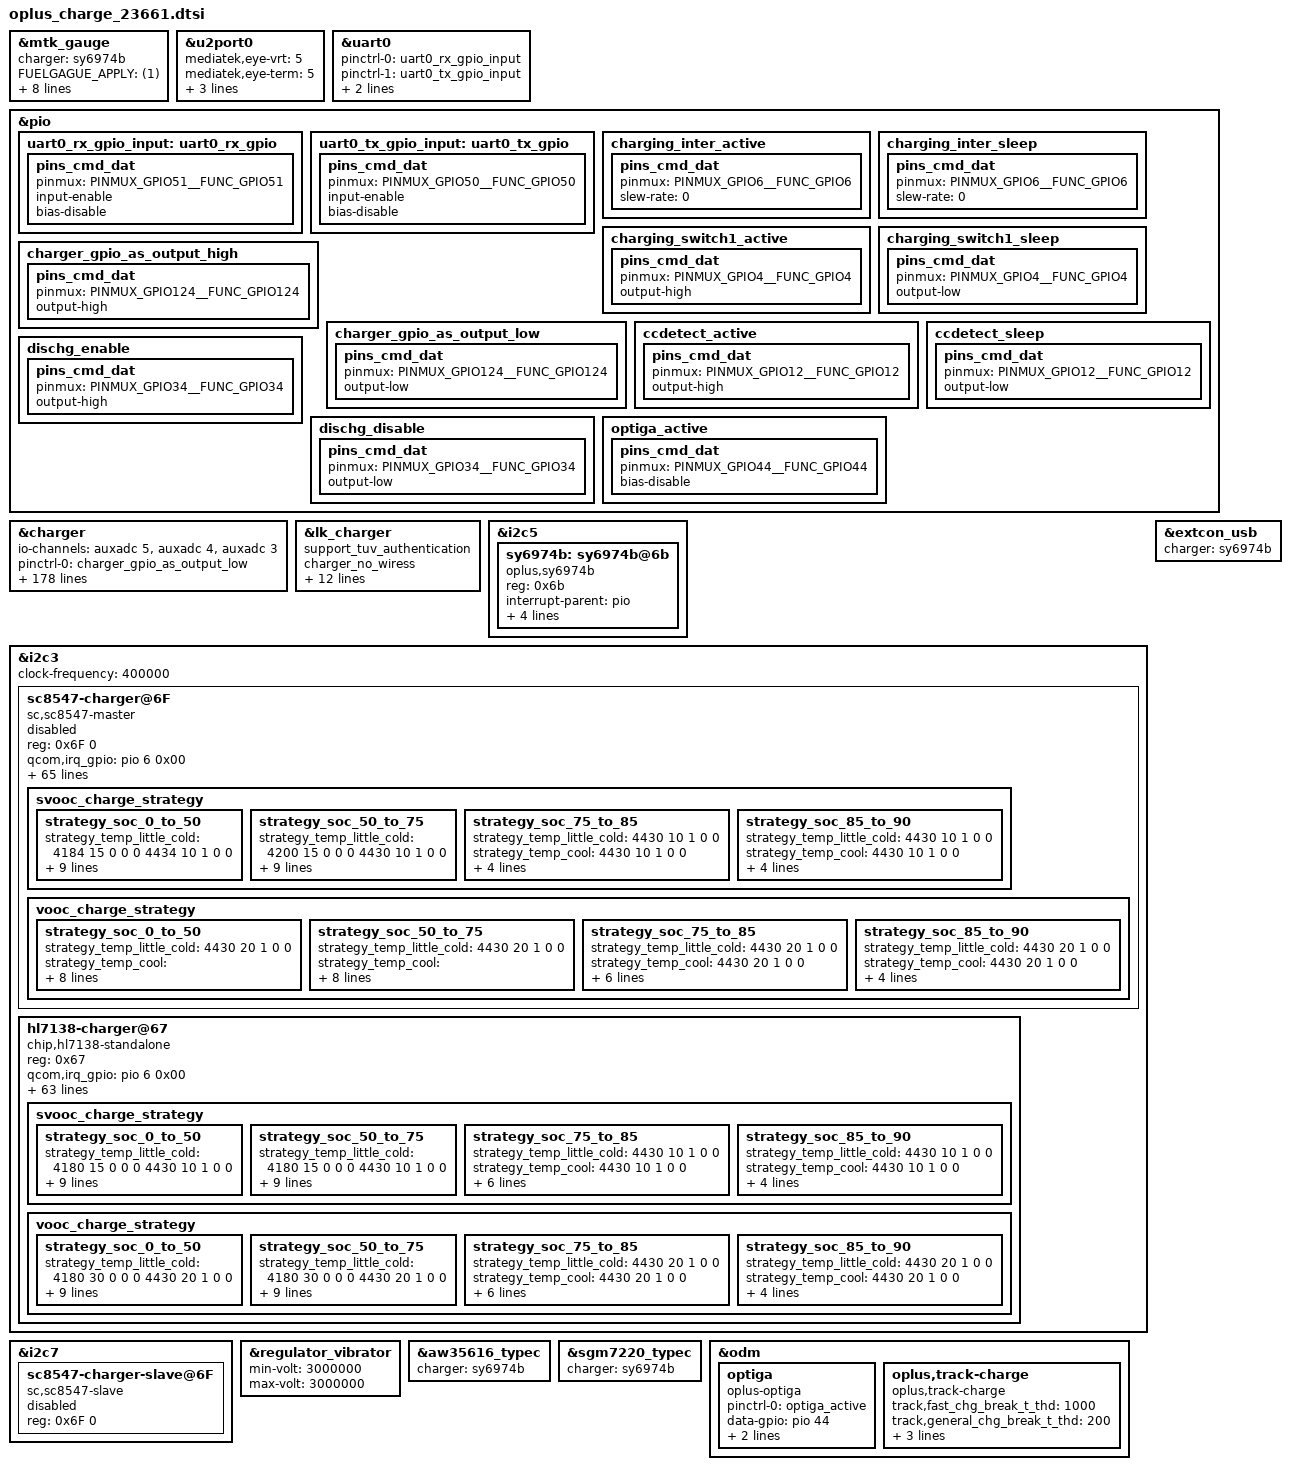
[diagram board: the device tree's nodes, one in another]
// SPDX-License-Identifier: GPL-2.0-only
/*
* Copyright (C) 2021-2020 Oplus. All rights reserved.
*/

/*
 *
 * CPU:MT6835 Chongqing
 * UTXD0 -->GPIO50
 * URXD0 -->GPIO51
 * I2C
 * MASTER_CHG/CCLOGIC --> I2C5
 * IRQB
 * EINT_CHG_1 (cp1 irq)                -->GPIO6
 * EINT_CHG_2 (cp2 irq)                -->GPIO18
 * CC_CNTL_INT_N(cc login irq)          --> GPIO12
 * CHG_INT(main irq)           --> GPIO3
 *
 * GPIO
 * MAIN/CCLOGIN_SCL               --> GPIO137(SCL5)
 * MAIN/CCLOGIN_SDA               --> GPIO138(SDA5)
 * USB_SWITCH_2(uart/vooc switch)      --> GPIO4
 * VBUS_SHORT(防烧口)           --> GPIO34
 * CHARGER_PUMP1_SCL               --> GPIO133(CP1_SCL3)
 * CHARGER_PUMP1_SDA               --> GPIO134(CP1_SDA3)
 * CHARGER_PUMP2_SCL               --> GPIO141(CP2_SCL7)
 * CHARGER_PUMP2_SDA               --> GPIO142(CP2_SDA7)
 * USB_SWITCH_1(usb/uart&vooc switch)    --> GPIO124
 * SEC_IC (加密电池GPIO for 67W)    --> GPIO44
 *
 * AP_AUXADC:
 * 0				--> FLASH_LED1_NTC
 * 1				--> NTC_USBCON_TEM (BTB VBUS旁)
 * 2				--> NTC_CHARGE (充电IC旁)
 * 3				--> USB_TEM2_ADC (BB_USB_ADC2 r/l?)
 * 4				--> USB_TEM1_ADC (BB_USB_ADC1)
 * 5				--> BAT_ID_ADC_OUT   (注意：33W 时用的是BAT_ID_ADC_OUT ,67W时用的是 BATThermal_1)
 * 6				--> NTC_charging （充电座子旁）
 * 7				-->
 * 8				-->
 */


#include <dt-bindings/iio/mt635x-auxadc.h>
#include <dt-bindings/pinctrl/mt6373-pinfunc.h>
#include <dt-bindings/pinctrl/mt65xx.h>
#include "oplus_chg.h"
/* charge start */

&mtk_gauge {
	status = "okay";
	charger = <&sy6974b>;
	FUELGAGUE_APPLY = <(1)>;
	BATT_ID_FAST_CHECK = <(1)>;
	io-channels = <&pmic_adc AUXADC_BAT_TEMP>,
				<&pmic_adc AUXADC_BATADC>,
				<&pmic_adc AUXADC_VBIF>,
				<&pmic_adc AUXADC_IMP>,
				<&pmic_adc AUXADC_IMIX_R>,
				<&pmic_adc AUXADC_VCDT>,
				<&auxadc 5>;
	io-channel-names = "pmic_battery_temp",
					"pmic_battery_voltage",
					"pmic_bif_voltage",
					"pmic_ptim_voltage",
					"pmic_ptim_r",
					"pmic_vcdt_voltage",
					 "auxadc5-batt_id_v";


    //IS_SUBBOARD_TEMP_SUPPORT = <(1)>;
	Enable_Is_Force_Full = <(1)>;
	DIM2_TABLE_DISTINGUISH = <(1)>;
	#include "mediatek/bat_setting/mt6835_chongqing_battery_table_33w.dtsi"
	#include "mediatek/bat_setting/mt6835_chongqing_battery_prop_dim2_ext_33w.dtsi"
};

&u2port0 {
    mediatek,eye-vrt = <5>;
    mediatek,eye-term = <5>;
    mediatek,rev4 = <1>;
    mediatek,discth = <9>;
    mediatek,rx-sqth = <5>;
};


&uart0 {
	pinctrl-names = "uart0_rx_gpio", "uart0_tx_gpio";
	pinctrl-0 = <&uart0_rx_gpio_input>;
	pinctrl-1 = <&uart0_tx_gpio_input>;
	status = "okay";

	txpin = <50>;
	rxpin = <51>;
};

&pio {
	uart0_rx_gpio_input: uart0_rx_gpio {
		pins_cmd_dat {
			pinmux = <PINMUX_GPIO51__FUNC_GPIO51>;
			input-enable;
			bias-disable;
		};
	};

	uart0_tx_gpio_input: uart0_tx_gpio {
		pins_cmd_dat {
			pinmux = <PINMUX_GPIO50__FUNC_GPIO50>;
			input-enable;
			bias-disable;
		};
	};
};


&charger {
//auxadc5temp 待配置，doki上是sub_bat_tem
	io-channels = <&auxadc 5>,<&auxadc 4>,<&auxadc 3>;
	io-channel-names = "auxadc5temp","usb_temp_v_l","usb_temp_v_r";

	pinctrl-names = "charger_gpio_as_output_low","charger_gpio_as_output_high",
					"ccdetect_active","ccdetect_sleep","dischg_enable","dischg_disable";
	pinctrl-0 = <&charger_gpio_as_output_low>;
	pinctrl-1 = <&charger_gpio_as_output_high>;
	pinctrl-2 = <&ccdetect_active>;
	pinctrl-3 = <&ccdetect_sleep>;
	pinctrl-4 = <&dischg_enable>;
	pinctrl-5 = <&dischg_disable>;

	gauge = <&mtk_gauge>;
	charger = <&sy6974b>;

	//for oplus chg framework:
	qcom,pps_support_type = <0>;
	qcom,pd_input_current_charger_ma = <2000>;
	qcom,qc_input_current_charger_ma = <2000>;
	qcom,input_current_charger_ma = <2200>;
	qcom,input_current_usb_ma = <500>;
	qcom,input_current_cdp_ma = <1500>;
	qcom,input_current_camera_ma = <1200>;
	qcom,input_current_calling_ma = <1500>;

	qcom,led_warm_bat_decidegc = <350>;
	qcom,led_high_bat_decidegc = <370>;
	qcom,input_current_led_ma = <1200>;
	qcom,input_current_led_ma_high = <1200>;
	qcom,input_current_led_ma_warm = <1500>;
	qcom,input_current_led_ma_normal = <2000>;
	qcom,input_current_led_ma_forcmcc = <500>;
	qcom,input_current_led_ma_limit_high = <1200>;

	qcom,vooc_temp_bat_normal_decidegc = <350>;
	qcom,vooc_temp_bat_warm_decidegc = <370>;
	qcom,vooc_temp_bat_hot_decidegc = <440>;
	qcom,input_current_vooc_led_ma_high = <1200>;
	qcom,input_current_vooc_led_ma_warm = <1800>;
	qcom,input_current_vooc_led_ma_normal = <3600>;
	qcom,input_current_vooc_ma_normal = <3600>;
	qcom,input_current_vooc_ma_warm = <3200>;
	qcom,input_current_vooc_ma_high = <2200>;

	qcom,overtemp_bat_decidegc = <400>;
	qcom,iterm_disabled = <0>;
	//sw_full_count = <25>;
	qcom,iterm_ma = <255>;
	qcom,recharge-mv = <100>;

	qcom,batt_capacity_mah = <5000>; /*typical capacity*/
	qcom,usb_high_than_bat_decidegc = <168>;

	qcom,removed_bat_decidegc = <400>;  /* < -15C */

	qcom,cold_bat_decidegc = <100>;  /* -10C ~ 0C */
	qcom,temp_cold_vfloat_mv = <4435>;
	qcom,temp_freeze_fastchg_current_ma_high = <900>;
	qcom,temp_freeze_fastchg_current_ma_low = <900>;
	qcom,temp_freeze_fastchg_current_ma = <900>;
	qcom,temp_cold_fastchg_current_ma = <900>;

	qcom,little_cold_bat_decidegc = <0>;    /* 0C ~ 5C */
	qcom,temp_little_cold_vfloat_mv = <4435>;
	qcom,temp_little_cold_fastchg_current_ma_high = <2200>;
	qcom,temp_little_cold_fastchg_current_ma_low = <2200>;
	qcom,temp_little_cold_fastchg_current_ma = <2200>;
	qcom,qc_temp_little_cold_fastchg_current_ma_high = <2594>;
	qcom,qc_temp_little_cold_fastchg_current_ma_low = <3300>;
	qcom,pd_temp_little_cold_fastchg_current_ma_high = <2594>;
	qcom,pd_temp_little_cold_fastchg_current_ma_low = <3300>;

	qcom,cool_bat_decidegc = <50>;  /* 5C ~ 12C */
	qcom,temp_cool_vfloat_mv = <4435>;
	qcom,temp_cool_fastchg_current_ma_high = <2200>;
	qcom,temp_cool_fastchg_current_ma_low = <2200>;
	qcom,qc_temp_cool_fastchg_current_ma_high = <3300>;
	qcom,qc_temp_cool_fastchg_current_ma_low = <3300>;
	qcom,pd_temp_cool_fastchg_current_ma_high = <3300>;
	qcom,pd_temp_cool_fastchg_current_ma_low = <3300>;

	qcom,little_cool_bat_decidegc = <120>;  /* 12C ~ 16C */
	qcom,temp_little_cool_vfloat_mv = <4435>;
	qcom,temp_little_cool_fastchg_current_ma = <2200>;
	qcom,pd_temp_little_cool_fastchg_current_ma = <3300>;
	qcom,qc_temp_little_cool_fastchg_current_ma = <3300>;

	qcom,normal_bat_decidegc = <160>;       /* 16C ~ 45C */
	qcom,temp_normal_vfloat_mv = <4435>;
	qcom,temp_normal_fastchg_current_ma = <2200>;
	qcom,pd_temp_normal_fastchg_current_ma = <3300>;
	qcom,qc_temp_normal_fastchg_current_ma = <3300>;

	qcom,warm_bat_decidegc = <450>;         /* 45C ~ 53C */ /*8pin Bat Vooc project need add 3 degree C*/
	qcom,temp_warm_vfloat_mv = <4130>;
	qcom,temp_warm_fastchg_current_ma = <1300>;
	qcom,pd_temp_warm_fastchg_current_ma = <1300>;
	qcom,qc_temp_warm_fastchg_current_ma = <1300>;
	qcom,temp_warm_fastchg_current_ma_led_on = <500>;

	qcom,hot_bat_decidegc = <530>;  /* > 53C */

	qcom,non_standard_vfloat_mv = <3980>;
	qcom,non_standard_fastchg_current_ma = <512>;

	qcom,short_c_bat_cv_mv = <4330>;
	qcom,short_c_bat_vfloat_mv = <3800>;
	qcom,short_c_bat_fastchg_current_ma = <512>;
	qcom,short_c_bat_vfloat_sw_limit = <3750>;

	qcom,cold_vfloat_sw_limit = <4385>;
	qcom,little_cold_vfloat_sw_limit = <4385>;
	qcom,cool_vfloat_sw_limit = <4385>;
	qcom,little_cool_vfloat_sw_limit = <4385>;
	qcom,normal_vfloat_sw_limit = <4385>;
	qcom,warm_vfloat_sw_limit = <4080>;
	qcom,non_standard_vfloat_sw_limit = <3930>;

	qcom,max_chg_time_sec = <72000>;
	qcom,charger_hv_thr = <10000>;
	qcom,charger_recv_thr = <9800>;
	qcom,charger_lv_thr = <3400>;
	qcom,vbatt_full_thr = <4400>;
	qcom,vbatt_hv_thr = <4600>;

	qcom,vfloat_step_mv = <16>;
	qcom,non_standard_vfloat_over_sw_limit = <3990>;
	qcom,cold_vfloat_over_sw_limit = <4445>;
	qcom,little_cold_vfloat_over_sw_limit = <4445>;
	qcom,cool_vfloat_over_sw_limit = <4445>;
	qcom,little_cool_vfloat_over_sw_limit = <4445>;
	qcom,normal_vfloat_over_sw_limit = <4440>;
	qcom,warm_vfloat_over_sw_limit = <4140>;

	qcom,vbatt_power_off = <3300>;
	qcom,vbatt_soc_1 = <3410>;
	qcom,vooc_project = <5>;
	qcom,vbatt_num = <1>;
	qcom,new_ui_warning_support;
	qcom,smart_charging_screenoff;
	qcom,smart_charge_version = <1>;

	qcom,normal_vterm_hw_inc = <18>;
	qcom,non_normal_vterm_hw_inc = <18>;
	qcom,usbtemp_batttemp_gap = <12>;

	qcom,ff1_normal_fastchg_ma = <1500>; /*12C~35c*/
	qcom,ff1_warm_fastchg_ma = <1500>;	/* 35C ~ 40c */
	qcom,ff1_exit_step_ma = <400>;
	qcom,ff1_warm_exit_step_ma = <300>;

	qcom,ffc2_normal_fastchg_ma = <1200>;/*12C~35c*/
	qcom,ffc2_warm_fastchg_ma = <1300>;	/* 35C ~ 40c */
	qcom,ffc2_temp_warm_decidegc = <350>;
	qcom,ffc2_temp_high_decidegc = <400>;
	qcom,ffc2_temp_low_decidegc = <120>;
	qcom,ffc2_exit_step_ma = <100>;
	qcom,ffc2_warm_exit_step_ma = <100>;

	qcom,ffc_normal_vfloat_sw_limit = <4475>;
	qcom,ffc_temp_normal_vfloat_mv = <4550>;
	qcom,ffc_normal_vfloat_over_sw_limit = <4550>;
	qcom,ffc_warm_vfloat_sw_limit = <4475>;

	qcom,ffc2_normal_vfloat_sw_limit = <4475>;
	qcom,ffc2_temp_normal_vfloat_mv = <4550>;
	qcom,ffc2_normal_vfloat_over_sw_limit = <4550>;
	qcom,ffc2_warm_vfloat_sw_limit = <4475>;


	qcom,default_iterm_ma = <255>;
	qcom,default_temp_normal_fastchg_current_ma = <2200>;
	qcom,default_normal_vfloat_sw_limit = <4385>;
	qcom,default_temp_normal_vfloat_mv = <4435>;
	qcom,default_normal_vfloat_over_sw_limit = <4445>;

	qcom,default_temp_little_cool_fastchg_current_ma = <2200>;
	qcom,default_little_cool_vfloat_sw_limit = <4385>;
	qcom,default_temp_little_cool_vfloat_mv = <4435>;
	qcom,default_little_cool_vfloat_over_sw_limit = <4445>;

	//for PD9V or QC9V
	qcom,vbatt_pdqc_to_5v_thr = <4500>;
	qcom,vbatt_pdqc_to_9v_thr = <4500>;

	//for control:
	//qcom,suspend_after_full;
	qcom,check_batt_full_by_sw;
	qcom,chg_ctrl_by_lcd;
	qcom,chg_ctrl_by_camera;
	qcom,chg_ctrl_by_calling;
	qcom,sw_vfloat_over_protect_enable;
	qcom,usbtemp_dischg_by_platpmic;
	qcom,ffc_support;
	qcom,chargerid_vol_disable;
	qcom,support_ntc_01c_precision;
	qcom,voocphy_support = <2>;
	//qcom,external_authenticate;
	qcom,chargerid_support;
	qcom,vooc_show_ui_soc_decimal;
	qcom,ui_soc_decimal_speedmin = <20>;//2A
	qcom,ccdetect_by_wd0;
	qcom,hvdcp_disabled; //do'not supprot hvdcp
	//GPIO config:
	qcom,chargerid_switch-gpio = <&pio 124 0x00>;/*USB_SWITCH_1*/
	qcom,dischg-gpio = <&pio 34 0x00>;/*VBUS_SHORT*/
	//qcom,ccdetect-gpio = <&pio 3 0x00>;

	qcom,vooc-max-input-volt-support = <10000>;     //10V
	qcom,vooc-max-input-current-support = <3000>;   //3A
};

&lk_charger {
	support_tuv_authentication;
	charger_no_wiress;
	//sub_board_temp_support;
	support_sdp_screenoff;
	support_sdp_backlight;
	support_4p48_single_battery;//待确定
	max_charger_voltage = <15000000>;
	boot_battery_voltage = <3400000>;
	usb_charger_current = <500000>;
	ac_charger_current = <2050000>;
	ac_charger_input_current = <1500000>;
	non_std_ac_charger_current = <750000>;
	charging_host_charger_current = <1500000>;
	ta_ac_charger_current = <1500000>;
	pd_charger_current = <500000>;
};

&i2c5 {
	sy6974b:sy6974b@6b {
		status = "okay";
		compatible = "oplus,sy6974b";
		reg = <0x6b>;

		interrupt-parent = <&pio>;
		interrupts = <3 IRQ_TYPE_EDGE_FALLING 3 0>;
		sy6974b-irq-gpio = <&pio 3 0x00>;
		/*pinctrl-names = "default";
		pinctrl-0 = <&sy6974b_int_default>;*/
		/*
		* Charger name
		* Main charger: primary_chg
		* Slave charger: secondary_chg
		*/
		charger_name = "primary_chg";
		qcom,batfet_reset_disable;      /*1:disable 0:enable*/
    };
};

&i2c3 {
	status = "okay";
	clock-frequency = <400000>;//400K
	sc8547-charger@6F{
		status = "disable";
		compatible = "sc,sc8547-master";
		reg = <0x6F 0>;

		qcom,irq_gpio = <&pio 6 0x00>;/*CP1_EINT*/
		interrupt-parent = <&pio>;
		interrupts = <6 0>;

		pinctrl-names = "switch1_act_switch2_act", "switch1_sleep_switch2_sleep",
					"charging_inter_active", "charging_inter_sleep";
		pinctrl-0 = <&charging_switch1_active>;
		pinctrl-1 = <&charging_switch1_sleep>;
		pinctrl-2 = <&charging_inter_active>;
		pinctrl-3 = <&charging_inter_sleep>;

		qcom,charging_switch1-gpio = <&pio 4 0x00>;/*USB_SWITCH_2*/

		/*qcom,voocphy_dual_cp_support;*/
		qcom,slave_cp_enable_thr = <1900>;		//2000-100mA
		qcom,slave_cp_disable_thr_high = <1600>;	//1500+100mA
		qcom,voocphy_current_default = <60>;

		qcom,svooc_cool_down_current_limit = <60 20 20 20 30 40 50 60 60 60 60 60 60 60 60>;
		qcom,vooc_cool_down_current_limit = <30 20 20 20 30 30 30 30 30 30 30 30 30 30 30>;

		qcom,vooc_multistep_initial_batt_temp = <1000>;

		qcom,vooc_strategy_normal_current = <100>;
		qcom,vooc_normal_to_little_cool_current = <100>;
		qcom,vooc_batt_over_high_temp = <500>;

		qcom,vooc-low-temp = <0>;
		qcom,vooc-high-temp = <500>;
		qcom,vooc-low-soc = <0>;
		qcom,vooc-high-soc = <90>;
		qcom,vooc-warm-allow-vol = <4000>;
		qcom,vooc-warm-allow-soc = <50>;

		qcom,vooc_little_cold_temp = <50>;
		qcom,vooc_cool_temp = <120>;
		qcom,vooc_little_cool_temp = <160>;
		qcom,vooc_normal_low_temp = <250>;
		qcom,vooc-normal-high-temp = <440>;

		qcom,vooc_strategy1_batt_high_temp0 = <400>;
		qcom,vooc_strategy1_batt_high_temp1 = <420>;
		qcom,vooc_strategy1_batt_high_temp2 = <430>;
		qcom,vooc_strategy1_batt_low_temp2 = <420>;
		qcom,vooc_strategy1_batt_low_temp1 = <410>;
		qcom,vooc_strategy1_batt_low_temp0 = <390>;

		qcom,vooc_strategy1_high_current0 = <40>;
		qcom,vooc_strategy1_high_current1 = <30>;
		qcom,vooc_strategy1_high_current2 = <20>;
		qcom,vooc_strategy1_low_current2 = <40>;
		qcom,vooc_strategy1_low_current1 = <50>;
		qcom,vooc_strategy1_low_current0 = <60>;

		qcom,voocphy_freq_mincore = <1800000>;
		qcom,voocphy_freq_midcore = <1800000>;
		qcom,voocphy_freq_maxcore = <1800000>;
		qcom,voocphy_current_change_timeout = <100>;

		qcom,voocphy_ibat_over_current = <7500>;
		qcom,voocphy_svooc_cp_max_ibus = <3500>;
		qcom,voocphy_vooc_cp_max_ibus = <3500>;
		qcom,voocphy_cp_max_ibus = <3500>;

		qcom,vooc_little_cold_full_voltage = <4434>;
		qcom,vooc_cool_full_voltage = <4434>;
		qcom,vooc_warm_full_voltage = <4130>;
		qcom,vooc_1time_full_voltage = <4484>;
		qcom,vooc_ntime_full_voltage = <4484>;
		qcom,low_curr_full_t1 = <120>;
		qcom,low_curr_full_t2 = <350>;
		qcom,low_curr_full_t3 = <430>;
		qcom,range1_low_curr_full = <1100 4470
						1000 4460
						900 4450>;
		qcom,range2_low_curr_full = <1200 4470
						1100 4460
						1000 4450>;

		svooc_batt_sys_curve = <0 1 0 1 0 0 0	// 4000mA
					1 1 1 1 0 0 0	// 4604mV
					0 0 1 1 0 1 0	// 2600mA
					1 1 1 1 0 0 0	// 4604mV
					0 0 0 1 0 1 1	// 1100mA
					1 1 1 1 0 0 0>;	// 4604mV

		vooc_batt_sys_curve =  <0 1 0 1 0 0 0	// 4000mA
					1 1 1 1 0 0 0	// 4604mV
					0 0 1 1 0 1 0	// 2600mA
					1 1 1 1 0 0 0	// 4604mV
					0 0 0 1 0 1 1	// 1100mA
					1 1 1 1 0 0 0>;	// 4604mV

		svooc_charge_strategy {
			strategy_soc_0_to_50 {
				strategy_temp_little_cold =	<4184 15 0 0 0
								 4434 10 1 0 0>;
				strategy_temp_cool =	<4184 20 0 0 0
								 4424 15 0 0 0
								 4434 10 1 0 0>;
				strategy_temp_little_cool =	<4454 20 0 0 0
								 4474 15 0 0 0
								 4484 10 1 0 0>;
				strategy_temp_normal_low =	<4200 30 0 1200 0 //min*60*1000/500
								 4454 25 0 1200 0 //min*60*1000/500
								 4454 23 0 0 0
								 4454 20 0 0 0
								 4474 17 0 0 0
								 4474 15 0 0 0
								 4484 10 1 0 0>;
				strategy_temp_normal_high =	<4200 30 0 1200 0 //min*60*1000/500
								 4454 25 0 1200 0 //min*60*1000/500
								 4454 23 0 0 0
								 4454 20 0 0 0
								 4474 17 0 0 0
								 4474 15 0 0 0
								 4484 10 1 0 0>;
				strategy_temp_warm = <4130 10 1 0 0>;
			};

			strategy_soc_50_to_75 {
				strategy_temp_little_cold =	<4200 15 0 0 0
								 4430 10 1 0 0>;
				strategy_temp_cool =	<4240 20 0 0 0
								 4240 15 0 0 0
								 4430 10 1 0 0>;
				strategy_temp_little_cool =	<4454 20 0 0 0
								 4474 15 0 0 0
								 4484 10 1 0 0>;
				strategy_temp_normal_low =	<4200 30 0 1200 0 //min*60*1000/500
								 4454 25 0 1200 0 //min*60*1000/500
								 4454 23 0 0 0
								 4454 20 0 0 0
								 4474 17 0 0 0
								 4474 15 0 0 0
								 4484 10 1 0 0>;
				strategy_temp_normal_high =	<4200 30 0 1200 0 //min*60*1000/500
								 4454 25 0 1200 0 //min*60*1000/500
								 4454 23 0 0 0
								 4454 20 0 0 0
								 4474 17 0 0 0
								 4474 15 0 0 0
								 4484 10 1 0 0>;
				strategy_temp_warm = <4130 10 1 0 0>;
			};

			strategy_soc_75_to_85 {
				strategy_temp_little_cold =	<4430 10 1 0 0>;
				strategy_temp_cool =	<4430 10 1 0 0>;
				strategy_temp_little_cool =	<4480 10 1 0 0>;
				strategy_temp_normal_low =	<4480 10 1 0 0>;
				strategy_temp_normal_high =	<4480 10 1 0 0>;
				strategy_temp_warm = <4130 10 1 0 0>;
			};

			strategy_soc_85_to_90 {
				strategy_temp_little_cold =	<4430 10 1 0 0>;
				strategy_temp_cool =	<4430 10 1 0 0>;
				strategy_temp_little_cool =	<4480 10 1 0 0>;
				strategy_temp_normal_low =	<4480 10 1 0 0>;
				strategy_temp_normal_high =	<4480 10 1 0 0>;
				strategy_temp_warm = <4130 10 1 0 0>;
			};
		};

		vooc_charge_strategy {
			strategy_soc_0_to_50 {
				strategy_temp_little_cold =	<4430 20 1 0 0>; /*0-5C*/
				strategy_temp_cool =	<4420 30 0 0 0
								 4430 20 1 0 0>;			/*5-12C*/
				strategy_temp_little_cool =	<4475 30 0 0 0
								 4480 20 1 0 0>;			/*12-16C*/
				strategy_temp_normal_low =	<4475 30 0 0 0
								 4480 20 1 0 0>;			/*16-25C*/
				strategy_temp_normal_high =	<4475 30 0 0 0
								 4480 20 1 0 0>;			/*25C-44C*/
				strategy_temp_warm = <4130 20 1 0 0>;
			};

			strategy_soc_50_to_75 {
				strategy_temp_little_cold =	<4430 20 1 0 0>;
				strategy_temp_cool =	<4420 30 0 0 0
								 4430 20 1 0 0>;
				strategy_temp_little_cool =	<4475 30 0 0 0
								 4480 20 1 0 0>;
				strategy_temp_normal_low =	<4475 30 0 0 0
								 4480 20 1 0 0>;
				strategy_temp_normal_high =	<4475 30 0 0 0
								 4480 20 1 0 0>;
				strategy_temp_warm = <4130 20 1 0 0>;
			};

			strategy_soc_75_to_85 {
				strategy_temp_little_cold =	<4430 20 1 0 0>;
				strategy_temp_cool =	<4430 20 1 0 0>;
				strategy_temp_little_cool =	<4480 20 1 0 0>;
				strategy_temp_normal_low =	<4475 30 0 0 0
								 4480 20 1 0 0>;
				strategy_temp_normal_high =	<4475 30 0 0 0
								 4480 20 1 0 0>;
				strategy_temp_warm = <4130 20 1 0 0>;
			};

			strategy_soc_85_to_90 {
				strategy_temp_little_cold =	<4430 20 1 0 0>;
				strategy_temp_cool =	<4430 20 1 0 0>;
				strategy_temp_little_cool =	<4480 20 1 0 0>;
				strategy_temp_normal_low =	<4480 20 1 0 0>;
				strategy_temp_normal_high =	<4480 20 1 0 0>;
				strategy_temp_warm = <4130 20 1 0 0>;
			};
		};

	};
	hl7138-charger@67{
		status = "okay";
		compatible = "chip,hl7138-standalone";
		reg = <0x67>;

		qcom,irq_gpio = <&pio 6 0x00>;
		interrupt-parent = <&pio>;
		interrupts = <6 0>;

		pinctrl-names = "switch1_act_switch2_act", "switch1_sleep_switch2_sleep",
				"charging_inter_active", "charging_inter_sleep";
		pinctrl-0 = <&charging_switch1_active>;
		pinctrl-1 = <&charging_switch1_sleep>;
		pinctrl-2 = <&charging_inter_active>;
		pinctrl-3 = <&charging_inter_sleep>;

		qcom,charging_switch1-gpio = <&pio 4 0x00>;

		qcom,voocphy_freq_mincore = <1800000>;
		qcom,voocphy_freq_midcore = <1800000>;
		qcom,voocphy_freq_maxcore = <1800000>;
		qcom,voocphy_current_change_timeout = <100>;

        /*qcom,voocphy_dual_cp_support;*/
		qcom,slave_cp_enable_thr = <1900>;		//2000-100mA
		qcom,slave_cp_disable_thr_high = <1600>;	//1500+100mA
		qcom,voocphy_current_default = <30>;

		qcom,svooc_cool_down_current_limit = <122 20 20 24 30 34 40 44 50 54 60 64 70 74 80>;
		qcom,vooc_cool_down_current_limit = <61 20 20 24 30 34 40 44 50 54 60 64 70 74 80>;

		qcom,vooc_little_cold_full_voltage = <4430>;
		qcom,vooc_cool_full_voltage = <4430>;
		qcom,vooc_warm_full_voltage = <4130>;
		qcom,vooc_1time_full_voltage = <4480>;
		qcom,vooc_ntime_full_voltage = <4480>;
		qcom,low_curr_full_t1 = <120>;
		qcom,low_curr_full_t2 = <350>;
		qcom,low_curr_full_t3 = <430>;
		qcom,range1_low_curr_full = <1150 4480
						1050 4475
						950 4460
						850 4450
						750 4440>;
		qcom,range2_low_curr_full = <1250 4480
						1150 4475
						1050 4460
						950 4450
						850 4440>;

		qcom,vooc_multistep_initial_batt_temp = <1000>;
		qcom,vooc_little_cool_temp = <160>;
		qcom,vooc_cool_temp = <120>;
		qcom,vooc_little_cold_temp = <50>;
		qcom,vooc_normal_low_temp = <250>;
		qcom,vooc_strategy_normal_current = <100>;
		qcom,vooc_normal_to_little_cool_current = <100>;
		qcom,vooc_batt_over_high_temp = <510>;
		qcom,vooc-low-temp = <0>;
		qcom,vooc-high-temp = <500>;
		qcom,vooc-low-soc = <0>;
		qcom,vooc-high-soc = <90>;
		qcom,vooc-normal-high-temp = <430>;
		qcom,vooc-warm-allow-vol = <4000>;
		qcom,vooc-warm-allow-soc = <50>;

		qcom,vooc_strategy1_batt_high_temp0 = <385>;
		qcom,vooc_strategy1_batt_high_temp1 = <395>;
		qcom,vooc_strategy1_batt_high_temp2 = <420>;
		qcom,vooc_strategy1_batt_low_temp2 = <410>;
		qcom,vooc_strategy1_batt_low_temp1 = <385>;
		qcom,vooc_strategy1_batt_low_temp0 = <375>;

		qcom,vooc_strategy1_high_current0 = <60>;
		qcom,vooc_strategy1_high_current1 = <60>;
		qcom,vooc_strategy1_high_current2 = <40>;
		qcom,vooc_strategy1_low_current2 = <60>;
		qcom,vooc_strategy1_low_current1 = <60>;
		qcom,vooc_strategy1_low_current0 = <100>;

		qcom,voocphy_ibat_over_current = <7500>;
		qcom,voocphy_cp_max_ibus = <3500>;

		svooc_batt_sys_curve = <0 0 1 1 1 1 0	// 3000mA
					0 0 0 0 0 0 1	// 3414mV
					0 0 1 0 1 0 0	// 2000mA
					1 1 1 0 0 1 0	// 4550mV
					0 0 0 1 0 1 0	// 1000mA
					1 1 1 0 0 1 0>;	// 4550mV

		vooc_batt_sys_curve =  <0 0 1 1 1 1 0	// 3000mA
					0 0 0 0 0 0 1	// 3414mV
					0 0 1 0 1 0 0	// 2000mA
					1 1 1 0 0 1 0	// 4550mV
					0 0 0 1 0 1 0	// 1000mA
					1 1 1 0 0 1 0>;	// 4550mV

		svooc_charge_strategy {
			strategy_soc_0_to_50 {
				strategy_temp_little_cold =	<4180 15 0 0 0
								 4430 10 1 0 0>;
				strategy_temp_cool =		<4180 20 0 0 0
								 4420 15 0 0 0
								 4430 10 1 0 0>;
				strategy_temp_little_cool = 	<4450 20 0 0 0
								 4470 15 0 0 0
								 4480 10 1 0 0>;
				strategy_temp_normal_low =	<4200 30 0 1200 0
								 4450 25 0 1200 0
								 4450 23 0 0 0
								 4450 20 0 0 0
								 4470 15 0 0 0
								 4480 10 1 0 0>;
				strategy_temp_normal_high =	<4200 30 0 1200 0
								 4450 25 0 1200 0
								 4450 23 0 0 0
								 4450 20 0 0 0
								 4470 15 0 0 0
								 4480 10 1 0 0>;
				strategy_temp_warm =		<4130 10 1 0 0>;
			};

			strategy_soc_50_to_75 {
				strategy_temp_little_cold =	<4180 15 0 0 0
								 4430 10 1 0 0>;
				strategy_temp_cool =		<4180 20 0 0 0
								 4420 15 0 0 0
								 4430 10 1 0 0>;
				strategy_temp_little_cool =	<4450 20 0 0 0
								 4470 15 0 0 0
								 4480 10 1 0 0>;
				strategy_temp_normal_low =	<4450 25 0 1200 0
								 4450 23 0 0 0
								 4450 20 0 0 0
								 4470 15 0 0 0
								 4480 10 1 0 0>;
				strategy_temp_normal_high =	<4450 25 0 1200 0
								 4450 23 0 0 0
								 4450 20 0 0 0
								 4470 15 0 0 0
								 4480 10 1 0 0>;
				strategy_temp_warm =		<4130 10 1 0 0>;
			};

			strategy_soc_75_to_85 {
				strategy_temp_little_cold = 	<4430 10 1 0 0>;
				strategy_temp_cool =		<4430 10 1 0 0>;
				strategy_temp_little_cool =	<4480 10 1 0 0>;
				strategy_temp_normal_low =	<4470 15 0 0 0
								 4480 10 1 0 0>;
				strategy_temp_normal_high =	<4470 15 0 0 0
								 4480 10 1 0 0>;
				strategy_temp_warm =		<4130 10 1 0 0>;
			};

			strategy_soc_85_to_90 {
				strategy_temp_little_cold = 	<4430 10 1 0 0>;
				strategy_temp_cool =		<4430 10 1 0 0>;
				strategy_temp_little_cool =	<4480 10 1 0 0>;
				strategy_temp_normal_low =	<4480 10 1 0 0>;
				strategy_temp_normal_high =	<4480 10 1 0 0>;
				strategy_temp_warm =		<4130 10 1 0 0>;
			};
		};

		vooc_charge_strategy {
			strategy_soc_0_to_50 {
				strategy_temp_little_cold =	<4180 30 0 0 0
								 4430 20 1 0 0>;
				strategy_temp_cool =		<4420 30 0 0 0
								 4430 20 1 0 0>;
				strategy_temp_little_cool =	<4470 30 0 0 0
								 4480 20 1 0 0>;
				strategy_temp_normal_low =	<4470 30 0 0 0
								 4480 20 1 0 0>;
				strategy_temp_normal_high =	<4470 30 0 0 0
								 4480 20 1 0 0>;
				strategy_temp_warm =		<4130 20 1 0 0>;
			};

			strategy_soc_50_to_75 {
				strategy_temp_little_cold =	<4180 30 0 0 0
								 4430 20 1 0 0>;
				strategy_temp_cool =		<4420 30 0 0 0
								 4430 20 1 0 0>;
				strategy_temp_little_cool =	<4470 30 0 0 0
								 4480 20 1 0 0>;
				strategy_temp_normal_low =	<4450 40 0 0 0
								 4470 30 0 0 0
								 4480 20 1 0 0>;
				strategy_temp_normal_high =	<4450 40 0 0 0
								 4470 30 0 0 0
								 4480 20 1 0 0>;
				strategy_temp_warm =		<4130 20 1 0 0>;
			};

			strategy_soc_75_to_85 {
				strategy_temp_little_cold =	<4430 20 1 0 0>;
				strategy_temp_cool =		<4430 20 1 0 0>;
				strategy_temp_little_cool =	<4480 20 1 0 0>;
				strategy_temp_normal_low =	<4470 30 0 0 0
								 4480 20 1 0 0>;
				strategy_temp_normal_high =	<4470 30 0 0 0
								 4480 20 1 0 0>;
				strategy_temp_warm =		<4130 20 1 0 0>;
			};

			strategy_soc_85_to_90 {
				strategy_temp_little_cold =	<4430 20 1 0 0>;
				strategy_temp_cool =		<4430 20 1 0 0>;
				strategy_temp_little_cool =	<4480 20 1 0 0>;
				strategy_temp_normal_low =	<4480 20 1 0 0>;
				strategy_temp_normal_high =	<4480 20 1 0 0>;
				strategy_temp_warm =		<4130 20 1 0 0>;
			};
		};
	};
};
&i2c7 {
	status = "okay";
	sc8547-charger-slave@6F{
		status = "disabled";
		compatible = "sc,sc8547-slave";
		reg = <0x6F 0>;
	};
};


&pio {
/*CP1 EINT*/
	charging_inter_active: charging_inter_active {
		pins_cmd_dat {
			pinmux = <PINMUX_GPIO6__FUNC_GPIO6>;
			slew-rate = <0>;
		};
	};

	charging_inter_sleep: charging_inter_sleep {
		pins_cmd_dat {
			pinmux = <PINMUX_GPIO6__FUNC_GPIO6>;
			slew-rate = <0>;
		};
	};
/*usb_switch_2, for uart/vooc*/
	charging_switch1_active: charging_switch1_active {
		pins_cmd_dat {
			pinmux = <PINMUX_GPIO4__FUNC_GPIO4>;
			output-high;
		};
	};

	charging_switch1_sleep: charging_switch1_sleep {
		pins_cmd_dat {
			pinmux = <PINMUX_GPIO4__FUNC_GPIO4>;
			output-low;
		};
	};
/*usb_switch_1, for usb/uart&vooc*/
	charger_gpio_as_output_high: charger_gpio_as_output_high {
		pins_cmd_dat {
			pinmux = <PINMUX_GPIO124__FUNC_GPIO124>;
			output-high;
		};
	};
	charger_gpio_as_output_low: charger_gpio_as_output_low {
		pins_cmd_dat {
			pinmux = <PINMUX_GPIO124__FUNC_GPIO124>;
			output-low;
		};
	};
/*CC_INTB*/
	ccdetect_active: ccdetect_active {
		pins_cmd_dat {
			pinmux = <PINMUX_GPIO12__FUNC_GPIO12>;
			output-high;
		};
	};
	ccdetect_sleep: ccdetect_sleep {
		pins_cmd_dat {
			pinmux = <PINMUX_GPIO12__FUNC_GPIO12>;
			output-low;
		};
	};
/*VBUS_SHORT*/
	dischg_enable: dischg_enable {
		pins_cmd_dat {
			pinmux = <PINMUX_GPIO34__FUNC_GPIO34>;
			output-high;
		};
	};
	dischg_disable: dischg_disable {
		pins_cmd_dat {
			pinmux = <PINMUX_GPIO34__FUNC_GPIO34>;
			output-low;
		};
	};
};

&regulator_vibrator{
	min-volt = <3000000>;
	max-volt = <3000000>;
};
/*&usb {
	charger = <&sy6974b>;
	status = "okay";
};*/

&extcon_usb {
	charger = <&sy6974b>;
	status = "okay";
};

&charger {
	charger = <&sy6974b>;
	status = "okay";
};

&aw35616_typec {
	charger = <&sy6974b>;
	status = "okay";
};

&sgm7220_typec {
	charger = <&sy6974b>;
	status = "okay";
};

&odm {
	optiga {
		compatible = "oplus-optiga";
		status = "ok";
		pinctrl-names = "optiga_active";
		pinctrl-0 = <&optiga_active>;
		data-gpio = <&pio 44 0x00>; /*SEC IC GPIO 加密电池*/
		cpu-id = <7>;
		key-id = <1>;
	};

	oplus,track-charge {
		compatible = "oplus,track-charge";
		track,fast_chg_break_t_thd = <1000>;
		track,general_chg_break_t_thd = <200>;
		track,voocphy_type = <2>;
		track,wired_max_power = <33000>;
		track,wired_fast_chg_scheme = <4>;
	};
};
&pio {
	optiga_active: optiga_active {
		pins_cmd_dat {
			pinmux = <PINMUX_GPIO44__FUNC_GPIO44>;
			//slew-rate = <1>;
			bias-disable;
		};
	};
};
/* chagrge end */

